# DPHY_RX0_VBUS2APB_WRAP_VBUSP_K3_DPHY_RX register map
Vendor: Texas Instruments
Peripheral module from a debugger description file (folder J7ES).
Registers are 32-bit, access per field, reset 0x0 unless marked. A register's access mark holds for its fields unless they carry their own. Offsets are as the file gives them; lines under a group give offsets from that group; [hi:lo] are bit positions; {n}, {i} and the like mark numbered series; 'fields as' and 'values as' point back to an identical list; <NAME> marks a mode.

## DPHY_RX0_VBUS2APB_WRAP_VBUSP_K3_DPHY_RX (part 1 of 2)
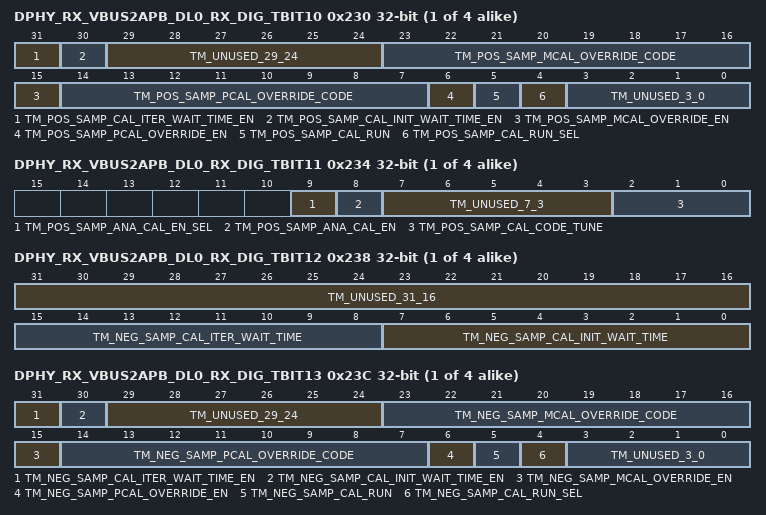
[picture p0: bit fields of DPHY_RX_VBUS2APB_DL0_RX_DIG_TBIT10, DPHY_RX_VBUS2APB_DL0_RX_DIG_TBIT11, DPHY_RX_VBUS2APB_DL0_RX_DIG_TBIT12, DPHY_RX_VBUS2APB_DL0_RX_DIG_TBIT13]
{0x230+0x100*i} DPHY_RX_VBUS2APB_DL{i}_RX_DIG_TBIT10 (i=0..3) — pos_samp_cal_ctrl_reg2
  [31] TM_POS_SAMP_CAL_ITER_WAIT_TIME_EN rw — posedge sampler calibration test mode iteration wait time enable
  [30] TM_POS_SAMP_CAL_INIT_WAIT_TIME_EN rw — posedge sampler calibration test mode initial wait time enable
  [29:24] TM_UNUSED_29_24 ro — RESERVED
  [23:16] TM_POS_SAMP_MCAL_OVERRIDE_CODE rw — posedge sampler calibration override mcal_code
  [15] TM_POS_SAMP_MCAL_OVERRIDE_EN rw — posedge sampler calibration mcal_code override en
  [14:7] TM_POS_SAMP_PCAL_OVERRIDE_CODE rw — posedge sampler calibration override pcal_code
  [6] TM_POS_SAMP_PCAL_OVERRIDE_EN rw — posedge sampler calibration pcal_code override en
  [5] TM_POS_SAMP_CAL_RUN rw — posedge sampler calibration test mode run
  [4] TM_POS_SAMP_CAL_RUN_SEL rw — posedge sampler calibration test mode selection
  [3:0] TM_UNUSED_3_0 ro — RESERVED
{0x234+0x100*i} DPHY_RX_VBUS2APB_DL{i}_RX_DIG_TBIT11 (i=0..3) — pos_samp_cal_ctrl_reg3
  [9] TM_POS_SAMP_ANA_CAL_EN_SEL rw — posedge sampler calibration analog calib enable selection
  [8] TM_POS_SAMP_ANA_CAL_EN rw — posedge sampler calibration analog calibration enable
  [7:3] TM_UNUSED_7_3 ro — RESERVED
  [2:0] TM_POS_SAMP_CAL_CODE_TUNE rw — posedge sampler calibration tune code
{0x238+0x100*i} DPHY_RX_VBUS2APB_DL{i}_RX_DIG_TBIT12 (i=0..3) — neg_samp_cal_ctrl_reg1
  [31:16] TM_UNUSED_31_16 ro — RESERVED
  [15:8] TM_NEG_SAMP_CAL_ITER_WAIT_TIME rw — negedge sampler calibration ieration time between codes
  [7:0] TM_NEG_SAMP_CAL_INIT_WAIT_TIME rw — negedge sampler calibration initial wait time
{0x23C+0x100*i} DPHY_RX_VBUS2APB_DL{i}_RX_DIG_TBIT13 (i=0..3) — neg_samp_cal_ctrl_reg2
  [31] TM_NEG_SAMP_CAL_ITER_WAIT_TIME_EN rw — negedge sampler calibration test mode iteration wait time enable
  [30] TM_NEG_SAMP_CAL_INIT_WAIT_TIME_EN rw — negedge sampler calibration test mode initial wait time enable
  [29:24] TM_UNUSED_29_24 ro — RESERVED
  [23:16] TM_NEG_SAMP_MCAL_OVERRIDE_CODE rw — negedge sampler calibration override mcal_code
  [15] TM_NEG_SAMP_MCAL_OVERRIDE_EN rw — negedge sampler calibration mcal_code override en
  [14:7] TM_NEG_SAMP_PCAL_OVERRIDE_CODE rw — negedge sampler calibration override pcal_code
  [6] TM_NEG_SAMP_PCAL_OVERRIDE_EN rw — negedge sampler calibration pcal_code override en
  [5] TM_NEG_SAMP_CAL_RUN rw — negedge sampler calibration test mode run
  [4] TM_NEG_SAMP_CAL_RUN_SEL rw — negedge sampler calibration test mode selection
  [3:0] TM_UNUSED_3_0 ro — RESERVED
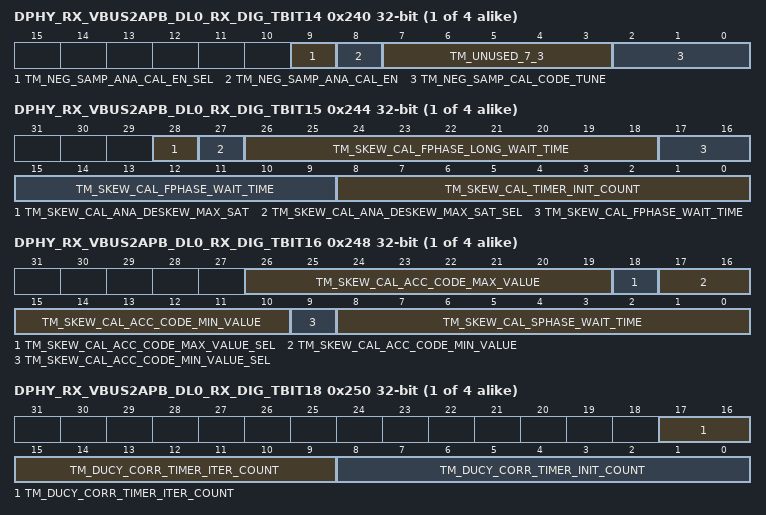
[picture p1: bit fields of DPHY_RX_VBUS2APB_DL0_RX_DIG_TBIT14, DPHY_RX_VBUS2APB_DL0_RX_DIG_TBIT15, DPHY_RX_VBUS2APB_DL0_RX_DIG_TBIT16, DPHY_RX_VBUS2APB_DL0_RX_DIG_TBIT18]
{0x240+0x100*i} DPHY_RX_VBUS2APB_DL{i}_RX_DIG_TBIT14 (i=0..3) — neg_samp_cal_ctrl_reg3
  [9] TM_NEG_SAMP_ANA_CAL_EN_SEL rw — negedge sampler calibration analog calib enable selection
  [8] TM_NEG_SAMP_ANA_CAL_EN rw — negedge sampler calibration analog calibration enable
  [7:3] TM_UNUSED_7_3 ro — RESERVED
  [2:0] TM_NEG_SAMP_CAL_CODE_TUNE rw — negedge sampler calibration tune code
{0x244+0x100*i} DPHY_RX_VBUS2APB_DL{i}_RX_DIG_TBIT15 (i=0..3) — skew_cal_fsm_reg1
  [28] TM_SKEW_CAL_ANA_DESKEW_MAX_SAT rw — skew calibration analog max satiration test mode enable
  [27] TM_SKEW_CAL_ANA_DESKEW_MAX_SAT_SEL rw — skew calibration analog max satiration selection
  [26:18] TM_SKEW_CAL_FPHASE_LONG_WAIT_TIME rw — skew calibration fast phase long wait time
  [17:9] TM_SKEW_CAL_FPHASE_WAIT_TIME rw — skew calibration fast phase wait time
  [8:0] TM_SKEW_CAL_TIMER_INIT_COUNT rw — skew calibration initial wait time
{0x248+0x100*i} DPHY_RX_VBUS2APB_DL{i}_RX_DIG_TBIT16 (i=0..3) — skew_cal_fsm_reg2
  [26:19] TM_SKEW_CAL_ACC_CODE_MAX_VALUE rw — skew calibration delay code test mode max value
  [18] TM_SKEW_CAL_ACC_CODE_MAX_VALUE_SEL rw — skew calibration max code test reg selection
  [17:10] TM_SKEW_CAL_ACC_CODE_MIN_VALUE rw — skew calibration delay code test mode min value
  [9] TM_SKEW_CAL_ACC_CODE_MIN_VALUE_SEL rw — skew calibration min code test reg selection
  [8:0] TM_SKEW_CAL_SPHASE_WAIT_TIME rw — skew calibration slow phase wait time
{0x24C+0x100*i} DPHY_RX_VBUS2APB_DL{i}_RX_DIG_TBIT17 (i=0..3) — skew_cal_fsm_reg3
  [7:0] TM_SKEW_CAL_DESKEW_START_CODE rw — skew calibration initial start code
{0x250+0x100*i} DPHY_RX_VBUS2APB_DL{i}_RX_DIG_TBIT18 (i=0..3) — ducy_corr_ctrl_reg1
  [17:9] TM_DUCY_CORR_TIMER_ITER_COUNT rw — duty cycle correction iteration wait time specified in this register will be considered when a non-zero value is speci fied here
  [8:0] TM_DUCY_CORR_TIMER_INIT_COUNT rw — duty cycle correction initial wait time specified in this register will be considered when a non-zero value is speci fied here
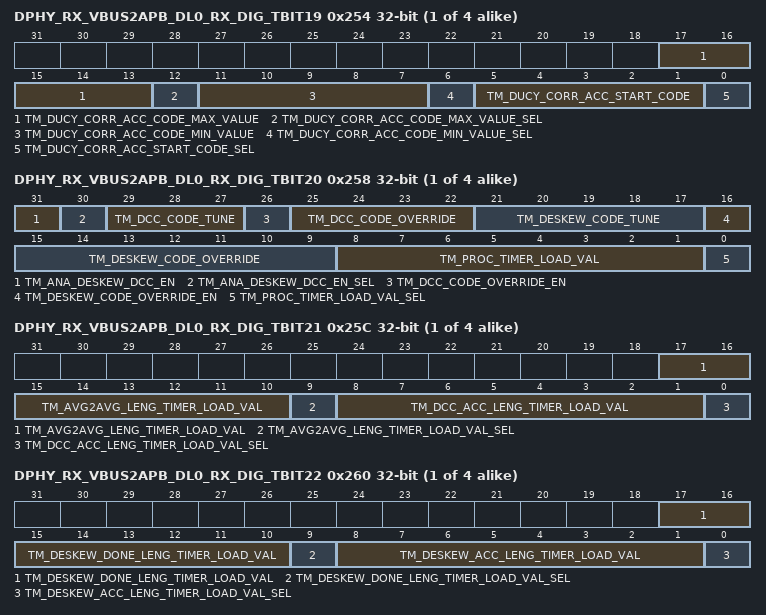
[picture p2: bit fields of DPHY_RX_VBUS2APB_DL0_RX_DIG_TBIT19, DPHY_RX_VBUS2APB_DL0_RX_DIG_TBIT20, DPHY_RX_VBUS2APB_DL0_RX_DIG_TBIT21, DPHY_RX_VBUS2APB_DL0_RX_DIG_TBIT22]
{0x254+0x100*i} DPHY_RX_VBUS2APB_DL{i}_RX_DIG_TBIT19 (i=0..3) — ducy_corr_ctrl_reg2
  [17:13] TM_DUCY_CORR_ACC_CODE_MAX_VALUE rw — duty cycle correction test mode max value
  [12] TM_DUCY_CORR_ACC_CODE_MAX_VALUE_SEL rw — duty cycle correction test mode max value selection
  [11:7] TM_DUCY_CORR_ACC_CODE_MIN_VALUE rw — duty cycle correction test mode min value
  [6] TM_DUCY_CORR_ACC_CODE_MIN_VALUE_SEL rw — duty cycle correction test mode min value selection
  [5:1] TM_DUCY_CORR_ACC_START_CODE rw — duty cycle correction test mode start code
  [0] TM_DUCY_CORR_ACC_START_CODE_SEL rw — duty cycle correction test mode start code selection
{0x258+0x100*i} DPHY_RX_VBUS2APB_DL{i}_RX_DIG_TBIT20 rw (i=0..3) — skew_cal_avg_reg1
  [31] TM_ANA_DESKEW_DCC_EN — test mode analog deskew enable
  [30] TM_ANA_DESKEW_DCC_EN_SEL — test mode deskew analog enable selection
  [29:27] TM_DCC_CODE_TUNE — duty cycle correction code tune
  [26] TM_DCC_CODE_OVERRIDE_EN — duty cycle correction code override enable
  [25:22] TM_DCC_CODE_OVERRIDE — duty cycle correction override code
  [21:17] TM_DESKEW_CODE_TUNE — skew calibration delay line code tune
  [16] TM_DESKEW_CODE_OVERRIDE_EN — skew calibration delay code override enable
  [15:9] TM_DESKEW_CODE_OVERRIDE — skew calibration delay line override code
  [8:1] TM_PROC_TIMER_LOAD_VAL — skew calibration process time test mode value
  [0] TM_PROC_TIMER_LOAD_VAL_SEL — skew calibration process time test mode value selection
{0x25C+0x100*i} DPHY_RX_VBUS2APB_DL{i}_RX_DIG_TBIT21 (i=0..3) — skew_cal_avg_reg2
  [17:10] TM_AVG2AVG_LENG_TIMER_LOAD_VAL rw — delay line code averaging to dcc code averaging wait time
  [9] TM_AVG2AVG_LENG_TIMER_LOAD_VAL_SEL rw — delay line code averaging to dcc code averaging wait time selection
  [8:1] TM_DCC_ACC_LENG_TIMER_LOAD_VAL rw — total number of dcc codes to be taken for averaging in test mode
  [0] TM_DCC_ACC_LENG_TIMER_LOAD_VAL_SEL rw — test mode selection value for test mode number of dcc codes under averaging
{0x260+0x100*i} DPHY_RX_VBUS2APB_DL{i}_RX_DIG_TBIT22 (i=0..3) — skew_cal_avg_reg3
  [17:10] TM_DESKEW_DONE_LENG_TIMER_LOAD_VAL rw — after skew calibration is done, length of wait timer
  [9] TM_DESKEW_DONE_LENG_TIMER_LOAD_VAL_SEL rw — test mode selection value for length of wait time after deskew
  [8:1] TM_DESKEW_ACC_LENG_TIMER_LOAD_VAL rw — number of deskew dealy codes to be taken for averaging
  [0] TM_DESKEW_ACC_LENG_TIMER_LOAD_VAL_SEL rw — tets mode selction for test mode number of delay line codes for averaging
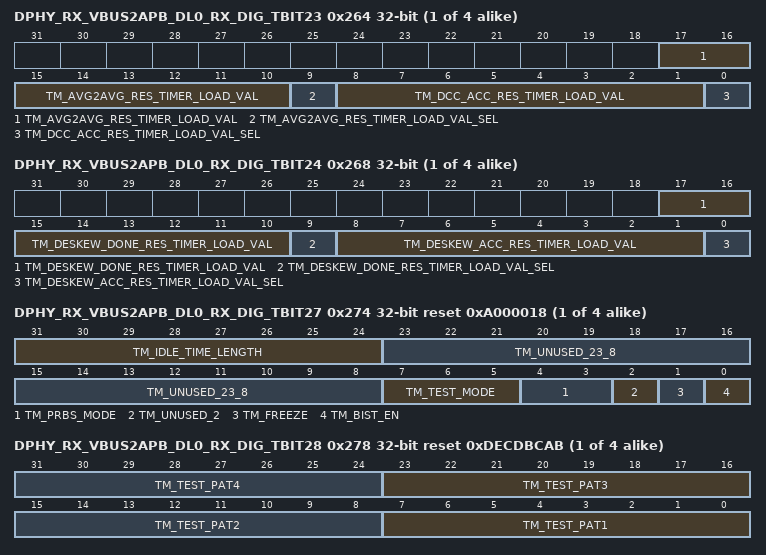
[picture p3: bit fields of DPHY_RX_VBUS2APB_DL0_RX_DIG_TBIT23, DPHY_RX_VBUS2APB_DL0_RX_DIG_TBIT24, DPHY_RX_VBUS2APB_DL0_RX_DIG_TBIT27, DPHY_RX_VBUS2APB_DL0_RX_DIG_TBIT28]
{0x264+0x100*i} DPHY_RX_VBUS2APB_DL{i}_RX_DIG_TBIT23 (i=0..3) — skew_cal_avg_reg4
  [17:10] TM_AVG2AVG_RES_TIMER_LOAD_VAL rw — resolution time of dcc averaging to deskew averaging wait time in test mode
  [9] TM_AVG2AVG_RES_TIMER_LOAD_VAL_SEL rw — test mode selection of resolution time of dcc averaging to deskew averaging wait time
  [8:1] TM_DCC_ACC_RES_TIMER_LOAD_VAL rw — resolution time of dcc averaging wait time in test mode
  [0] TM_DCC_ACC_RES_TIMER_LOAD_VAL_SEL rw — test mode selection of resolution time of dcc averaging wait time
{0x268+0x100*i} DPHY_RX_VBUS2APB_DL{i}_RX_DIG_TBIT24 (i=0..3) — skew_cal_avg_reg5
  [17:10] TM_DESKEW_DONE_RES_TIMER_LOAD_VAL rw — resolution time of deskew done wait time in test mode
  [9] TM_DESKEW_DONE_RES_TIMER_LOAD_VAL_SEL rw — test mode selcetion of resolution time of deskew done wait time in test mode
  [8:1] TM_DESKEW_ACC_RES_TIMER_LOAD_VAL rw — resolution time of deskew averaging wait time in test mode
  [0] TM_DESKEW_ACC_RES_TIMER_LOAD_VAL_SEL rw — tets mode selection of resolution time of deskew averaging wait time in test mode
{0x26C+0x100*i} DPHY_RX_VBUS2APB_DL{i}_RX_DIG_TBIT25 ro (i=0..3) — DIGITAL_EXTRA_CALIB_REG0
  [31:0] DIG_CALIB_EXTRA_TBIT0 — RESERVED
{0x270+0x100*i} DPHY_RX_VBUS2APB_DL{i}_RX_DIG_TBIT26 ro (i=0..3) — DIGITAL_EXTRA_CALIB_REG1
  [31:0] DIG_CALIB_EXTRA_TBIT1 — RESERVED
{0x274+0x100*i} DPHY_RX_VBUS2APB_DL{i}_RX_DIG_TBIT27 reset 0xA000018 (i=0..3) — bist_config_reg1
  [31:24] TM_IDLE_TIME_LENGTH rw — BIST_IDLE_TIME
  [23:8] TM_UNUSED_23_8 ro — RESERVED
  [7:5] TM_TEST_MODE rw — PRBS mode - when set to '1' PRBS mode is selected
  [4:3] TM_PRBS_MODE rw — BIST PRBS MODE 9 when 0x0
  [2] TM_UNUSED_2 ro — RESERVED
  [1] TM_FREEZE rw — Freeze the LFSR contents after every packet or frame
  [0] TM_BIST_EN rw — Enable signal for pattern checker
{0x278+0x100*i} DPHY_RX_VBUS2APB_DL{i}_RX_DIG_TBIT28 rw reset 0xDECDBCAB (i=0..3) — bist_config_reg2
  [8n-1:8n-8] TM_TEST_PAT{n} (n=1..4) — User registers to specify the BIST data{n} Based on the deault_mode setting design will consider either of the hard-value from RTL [or] the soft-value provided here
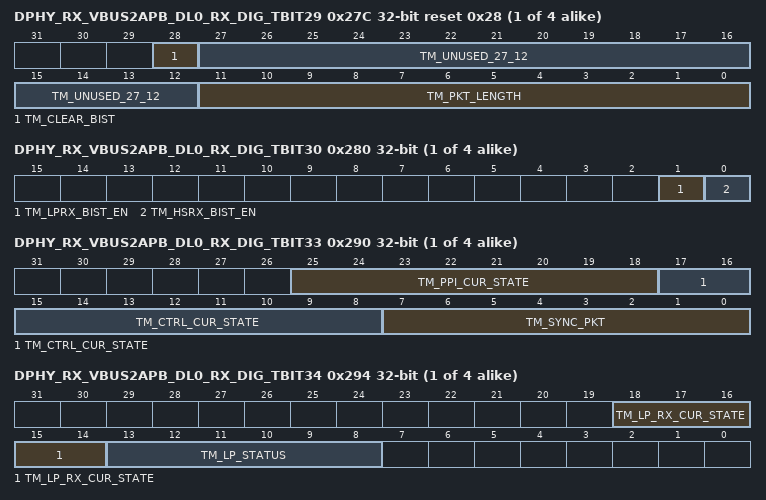
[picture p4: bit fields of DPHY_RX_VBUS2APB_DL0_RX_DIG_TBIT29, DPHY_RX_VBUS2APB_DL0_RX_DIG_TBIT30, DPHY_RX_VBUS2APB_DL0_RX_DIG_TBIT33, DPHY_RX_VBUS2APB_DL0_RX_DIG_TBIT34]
{0x27C+0x100*i} DPHY_RX_VBUS2APB_DL{i}_RX_DIG_TBIT29 reset 0x28 (i=0..3) — bist_config_reg3
  [28] TM_CLEAR_BIST rw — Setting this will clear all the BIST related flags and counters
  [27:12] TM_UNUSED_27_12 ro — RESERVED
  [11:0] TM_PKT_LENGTH rw — Based on the default_mode design will consider the run-length from design or the programmed value specified here
{0x280+0x100*i} DPHY_RX_VBUS2APB_DL{i}_RX_DIG_TBIT30 (i=0..3) — bist_config_reg4
  [1] TM_LPRX_BIST_EN rw — LPRX BIST is enbaled - rxda_lprx_bist_en - When '1', LP BIST is enabled
  [0] TM_HSRX_BIST_EN rw — HSRX BIST is enbaled - rxda_hsrx_bist_en - when '1', HS BIST is enabled
{0x284+0x100*i} DPHY_RX_VBUS2APB_DL{i}_RX_DIG_TBIT31 ro (i=0..3) — DIGITAL_EXTRA_TEST_REG1
  [31:0] DIG_EXTRA_FUNC_TBIT1 — RESERVED
{0x288+0x100*i} DPHY_RX_VBUS2APB_DL{i}_RX_DIG_TBIT32 ro (i=0..3) — DIGITAL_EXTRA_TEST_REG2
  [31:0] DIG_EXTRA_FUNC_TBIT2 — RESERVED
{0x28C+0x100*i} DPHY_RX_VBUS2APB_DL{i}_RX_ANA_TBIT2 ro (i=0..3) — ANA_TBIT0
  [31:0] ANA_READ_TBIT0 — Analog read register 0
{0x290+0x100*i} DPHY_RX_VBUS2APB_DL{i}_RX_DIG_TBIT33 ro (i=0..3) — deserialiser_fsm_status
  [25:18] TM_PPI_CUR_STATE — Current State of the SYNC detection FSM during the HS data receive mode or skew calibration mode
  [17:8] TM_CTRL_CUR_STATE — current state status of HS receive FSM
  [7:0] TM_SYNC_PKT — Status of received SYNC packet
{0x294+0x100*i} DPHY_RX_VBUS2APB_DL{i}_RX_DIG_TBIT34 ro (i=0..3) — lp_status
  [18:14] TM_LP_RX_CUR_STATE — Current state of LP receiver FSM
  [13:8] TM_LP_STATUS — Status of DP,DN pins of LPRX, LPCD, ULPRX respectively
{0x298+0x100*i} DPHY_RX_VBUS2APB_DL{i}_RX_DIG_TBIT35 ro (i=0..3) — DIGITAL_EXTRA_READ_REG0
  [31:0] DIG_EXTRA_READ_TBIT0 — RESERVED
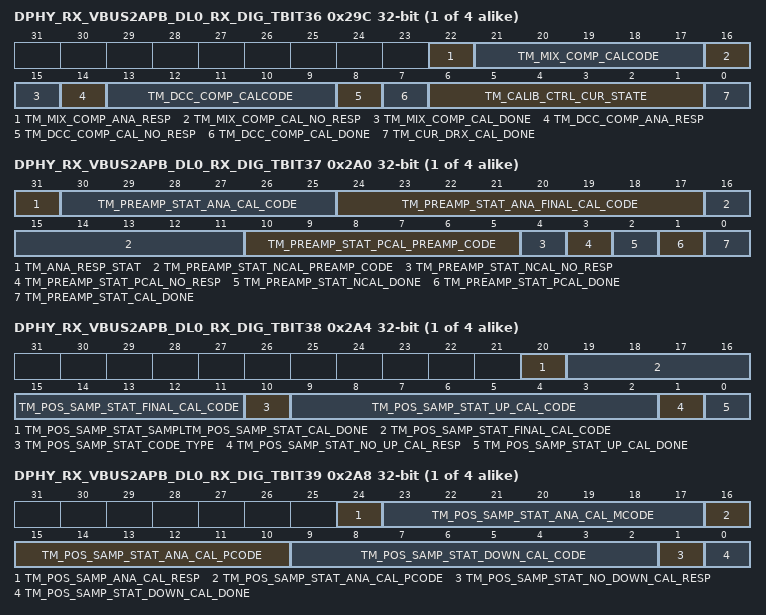
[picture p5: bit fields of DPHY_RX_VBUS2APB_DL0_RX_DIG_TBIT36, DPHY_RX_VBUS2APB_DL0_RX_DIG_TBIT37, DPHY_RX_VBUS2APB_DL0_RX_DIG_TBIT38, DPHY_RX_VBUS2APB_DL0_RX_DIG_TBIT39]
{0x29C+0x100*i} DPHY_RX_VBUS2APB_DL{i}_RX_DIG_TBIT36 ro (i=0..3) — dcc_mixer_comparator_calibration_stat
  [22] TM_MIX_COMP_ANA_RESP — Mixer comparator analog response
  [21:17] TM_MIX_COMP_CALCODE — Mixer comparator calibration code
  [16] TM_MIX_COMP_CAL_NO_RESP — Mixer comparator calibration has no response from analog
  [15] TM_MIX_COMP_CAL_DONE — Mixer comparator calibration is done properly
  [14] TM_DCC_COMP_ANA_RESP — Duty Cycle Comparator analog response
  [13:9] TM_DCC_COMP_CALCODE — Duty cycle corrector comparator calibration code
  [8] TM_DCC_COMP_CAL_NO_RESP — Duty cycle corrector comparator calibration has no response from analog
  [7] TM_DCC_COMP_CAL_DONE — Duty cycle corrector comparator calibration is done properly
  [6:1] TM_CALIB_CTRL_CUR_STATE — If struck, indicates calibration FSM current state
  [0] TM_CUR_DRX_CAL_DONE — Current DRX DPHY_RX_VBUS2APB_LANE calibrations are done
{0x2A0+0x100*i} DPHY_RX_VBUS2APB_DL{i}_RX_DIG_TBIT37 ro (i=0..3) — preamp_cal_status_reg1
  [31] TM_ANA_RESP_STAT — current analog or test mode response for which calibration is happening
  [30:25] TM_PREAMP_STAT_ANA_CAL_CODE — code going to analog
  [24:17] TM_PREAMP_STAT_ANA_FINAL_CAL_CODE — code decided to send to analog before tune
  [16:11] TM_PREAMP_STAT_NCAL_PREAMP_CODE — calib code in posedge_data run
  [10:5] TM_PREAMP_STAT_PCAL_PREAMP_CODE — calib code in negedge_data run
  [4] TM_PREAMP_STAT_NCAL_NO_RESP — negedge_data run ha sno response
  [3] TM_PREAMP_STAT_PCAL_NO_RESP — posedge_data run ha sno response
  [2] TM_PREAMP_STAT_NCAL_DONE — negedge_data cal run is done
  [1] TM_PREAMP_STAT_PCAL_DONE — posedge_data cal run is done
  [0] TM_PREAMP_STAT_CAL_DONE — preamp calibration is done
{0x2A4+0x100*i} DPHY_RX_VBUS2APB_DL{i}_RX_DIG_TBIT38 ro (i=0..3) — pos_samp_cal_status_reg1
  [20] TM_POS_SAMP_STAT_SAMPLTM_POS_SAMP_STAT_CAL_DONE — posedge sampler calibration is done
  [19:11] TM_POS_SAMP_STAT_FINAL_CAL_CODE — posedge sampler calbration final code
  [10] TM_POS_SAMP_STAT_CODE_TYPE — code type that is changing for posedge sampler
  [9:2] TM_POS_SAMP_STAT_UP_CAL_CODE — up check calib run code for posedge sampler
  [1] TM_POS_SAMP_STAT_NO_UP_CAL_RESP — up check calib run code has no analog response
  [0] TM_POS_SAMP_STAT_UP_CAL_DONE — up check calibration is done
{0x2A8+0x100*i} DPHY_RX_VBUS2APB_DL{i}_RX_DIG_TBIT39 ro (i=0..3) — pos_samp_cal_status_reg2
  [24] TM_POS_SAMP_ANA_CAL_RESP — test mode status of posedge sampler
  [23:17] TM_POS_SAMP_STAT_ANA_CAL_MCODE — final m code going to posedge sampler
  [16:10] TM_POS_SAMP_STAT_ANA_CAL_PCODE — final p code going to posedge sampler
  [9:2] TM_POS_SAMP_STAT_DOWN_CAL_CODE — down check calib run code for posedge sampler
  [1] TM_POS_SAMP_STAT_NO_DOWN_CAL_RESP — down check calib run code has no analog response
  [0] TM_POS_SAMP_STAT_DOWN_CAL_DONE — down check calibration is done
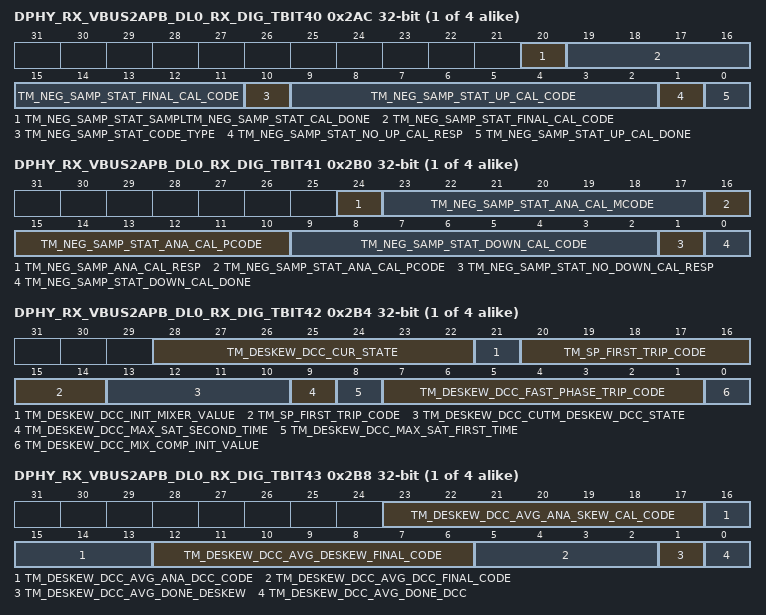
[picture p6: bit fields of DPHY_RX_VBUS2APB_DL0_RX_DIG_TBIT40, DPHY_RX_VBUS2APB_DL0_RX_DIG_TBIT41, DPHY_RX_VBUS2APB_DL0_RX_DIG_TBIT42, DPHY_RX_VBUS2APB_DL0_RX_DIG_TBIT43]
{0x2AC+0x100*i} DPHY_RX_VBUS2APB_DL{i}_RX_DIG_TBIT40 ro (i=0..3) — neg_samp_cal_status_reg1
  [20] TM_NEG_SAMP_STAT_SAMPLTM_NEG_SAMP_STAT_CAL_DONE — negedge sampler calibration is done
  [19:11] TM_NEG_SAMP_STAT_FINAL_CAL_CODE — negedge sampler calbration final code
  [10] TM_NEG_SAMP_STAT_CODE_TYPE — code type that is changing for negedge sampler
  [9:2] TM_NEG_SAMP_STAT_UP_CAL_CODE — up check calib run code for negedge sampler
  [1] TM_NEG_SAMP_STAT_NO_UP_CAL_RESP — up check calib run code has no analog response
  [0] TM_NEG_SAMP_STAT_UP_CAL_DONE — up check calibration is done
{0x2B0+0x100*i} DPHY_RX_VBUS2APB_DL{i}_RX_DIG_TBIT41 ro (i=0..3) — neg_samp_cal_status_reg2
  [24] TM_NEG_SAMP_ANA_CAL_RESP — test mode status of negedge sampler
  [23:17] TM_NEG_SAMP_STAT_ANA_CAL_MCODE — final m code going to negedge sampler
  [16:10] TM_NEG_SAMP_STAT_ANA_CAL_PCODE — final p code going to negedge sampler
  [9:2] TM_NEG_SAMP_STAT_DOWN_CAL_CODE — down check calib run code for negedge sampler
  [1] TM_NEG_SAMP_STAT_NO_DOWN_CAL_RESP — down check calib run code has no analog response
  [0] TM_NEG_SAMP_STAT_DOWN_CAL_DONE — down check calibration is done
{0x2B4+0x100*i} DPHY_RX_VBUS2APB_DL{i}_RX_DIG_TBIT42 ro (i=0..3) — skew_cal_fsm_status_reg1
  [28:22] TM_DESKEW_DCC_CUR_STATE — Duty cycle correction logic current state
  [21] TM_DESKEW_DCC_INIT_MIXER_VALUE — Duty cycle correction initial comparator value
  [20:14] TM_SP_FIRST_TRIP_CODE — slow phase first trip code
  [13:10] TM_DESKEW_DCC_CUTM_DESKEW_DCC_STATE — current state of the deskew FSM
  [9] TM_DESKEW_DCC_MAX_SAT_SECOND_TIME — if asserted, deskew FSM has gone into max saturation second time
  [8] TM_DESKEW_DCC_MAX_SAT_FIRST_TIME — if asserted, deskew FSM has got saturated once
  [7:1] TM_DESKEW_DCC_FAST_PHASE_TRIP_CODE — deskew FSM fast phase trip code
  [0] TM_DESKEW_DCC_MIX_COMP_INIT_VALUE — deskew algorithm mixer initial value
{0x2B8+0x100*i} DPHY_RX_VBUS2APB_DL{i}_RX_DIG_TBIT43 ro (i=0..3) — skew_cal_avg_status_reg1
  [23:17] TM_DESKEW_DCC_AVG_ANA_SKEW_CAL_CODE — final code going to delay line
  [16:13] TM_DESKEW_DCC_AVG_ANA_DCC_CODE — final code going to duty cycle corrector
  [12:6] TM_DESKEW_DCC_AVG_DESKEW_FINAL_CODE — delay line code before tuning
  [5:2] TM_DESKEW_DCC_AVG_DCC_FINAL_CODE — ducy code before tuning
  [1] TM_DESKEW_DCC_AVG_DONE_DESKEW — skew calibration is done
  [0] TM_DESKEW_DCC_AVG_DONE_DCC — duty cycle correction is done
{0x2BC+0x100*i} DPHY_RX_VBUS2APB_DL{i}_RX_DIG_TBIT44 ro (i=0..3) — skew_cal_avg_status_reg2
  [16:0] TM_DESKEW_DCC_AVG_CUTM_DESKEW_DCC_AVG_STATE — current state of deskew_dcc_averaging FSM
{0x2C0+0x100*i} DPHY_RX_VBUS2APB_DL{i}_RX_DIG_TBIT45 ro (i=0..3) — DIGITAL_CALIB_EXTRA_READ_REG0
  [31:0] DIG_CALIBRATION_EXTRA_READ_TBIT0 — RESERVED
{0x2C4+0x100*i} DPHY_RX_VBUS2APB_DL{i}_RX_DIG_TBIT46 ro (i=0..3) — DIGITAL_CALIB_EXTRA_READ_REG1
  [31:0] DIG_CALIBRATION_EXTRA_READ_TBIT1 — RESERVED
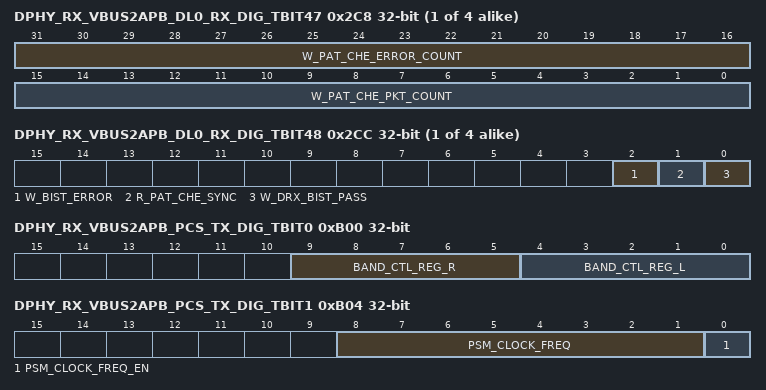
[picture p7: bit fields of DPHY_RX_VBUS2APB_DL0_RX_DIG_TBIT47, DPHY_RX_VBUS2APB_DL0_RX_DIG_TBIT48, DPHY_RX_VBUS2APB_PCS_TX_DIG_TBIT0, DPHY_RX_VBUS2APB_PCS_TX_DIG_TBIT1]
{0x2C8+0x100*i} DPHY_RX_VBUS2APB_DL{i}_RX_DIG_TBIT47 ro (i=0..3) — bist_status_reg1
  [31:16] W_PAT_CHE_ERROR_COUNT — BIST Pattern checker error count's live status can be obtained by poling this field
  [15:0] W_PAT_CHE_PKT_COUNT — BIST packet count's live status can be obtained by poling this field
{0x2CC+0x100*i} DPHY_RX_VBUS2APB_DL{i}_RX_DIG_TBIT48 ro (i=0..3) — bist_status_reg2
  [2] W_BIST_ERROR — Status of HS data path comparision outcome, '0' means pass
  [1] R_PAT_CHE_SYNC — Informs BIST Pattern checker is not in sync with pattern generator - Check polarity
  [0] W_DRX_BIST_PASS — Entire DRX has passed BIST when this bit's status is set
{0x2D0+0x100*i} DPHY_RX_VBUS2APB_DL{i}_RX_DIG_TBIT49 ro (i=0..3) — DIG_BIST_EXTRA_READ_REG0
  [31:0] DIG_BIST_EXTRA_READ_TBIT0 — RESERVED
{0x2D4+0x100*i} DPHY_RX_VBUS2APB_DL{i}_RX_DIG_TBIT50 ro (i=0..3) — DIG_EXTRA_READ_REG1
  [31:0] DIG_EXTRA_READ_TBIT1 — RESERVED
{0x2D8+0x100*i} DPHY_RX_VBUS2APB_DL{i}_RX_DIG_TBIT51 ro (i=0..3) — DIG_EXTRA_READ_REG2
  [31:0] DIG_EXTRA_READ_TBIT2 — RESERVED
0xB00 DPHY_RX_VBUS2APB_PCS_TX_DIG_TBIT0 — PHY_BAND_CONTROL
  [9:5] BAND_CTL_REG_R rw — Data Rate [80_100] MHz
  [4:0] BAND_CTL_REG_L rw — Data Rate [80_100] MHz
0xB04 DPHY_RX_VBUS2APB_PCS_TX_DIG_TBIT1 — PHY_PSM_CONFIG
  [8:1] PSM_CLOCK_FREQ rw — psm_clock freq value
  [0] PSM_CLOCK_FREQ_EN rw — take psm_clock_freq from tbit
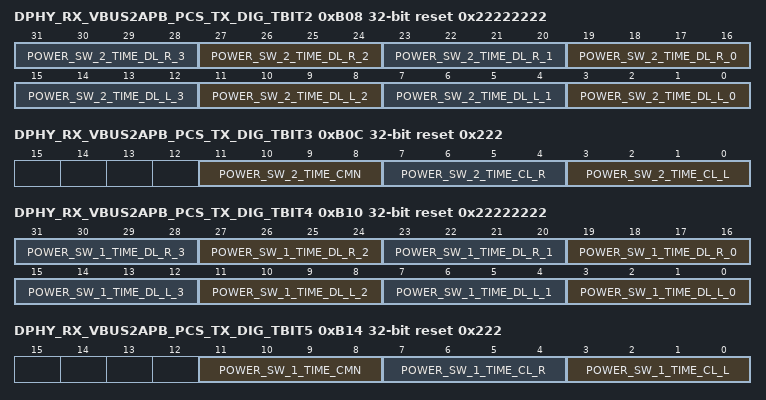
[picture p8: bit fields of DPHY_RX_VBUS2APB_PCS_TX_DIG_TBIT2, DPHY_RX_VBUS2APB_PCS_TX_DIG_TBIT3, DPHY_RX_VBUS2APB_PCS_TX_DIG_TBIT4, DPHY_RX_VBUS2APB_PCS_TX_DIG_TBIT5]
0xB08 DPHY_RX_VBUS2APB_PCS_TX_DIG_TBIT2 rw reset 0x22222222 — PHY_PI_PH2_DL_CONFIG
  [4n+19:4n+16] POWER_SW_2_TIME_DL_R_{n} (n=0..3), [4n+3:4n] POWER_SW_2_TIME_DL_L_{n} (n=0..3)
0xB0C DPHY_RX_VBUS2APB_PCS_TX_DIG_TBIT3 reset 0x222 — PHY_PI_PH2_CL_CMN_CONFIG
  [11:8] POWER_SW_2_TIME_CMN rw, [7:4] POWER_SW_2_TIME_CL_R rw, [3:0] POWER_SW_2_TIME_CL_L rw
0xB10 DPHY_RX_VBUS2APB_PCS_TX_DIG_TBIT4 rw reset 0x22222222 — PHY_PI_PH1_DL_CONFIG
  [4n+19:4n+16] POWER_SW_1_TIME_DL_R_{n} (n=0..3), [4n+3:4n] POWER_SW_1_TIME_DL_L_{n} (n=0..3)
0xB14 DPHY_RX_VBUS2APB_PCS_TX_DIG_TBIT5 reset 0x222 — PHY_PI_PH1_CL_CMN_CONFIG
  [11:8] POWER_SW_1_TIME_CMN rw, [7:4] POWER_SW_1_TIME_CL_R rw, [3:0] POWER_SW_1_TIME_CL_L rw
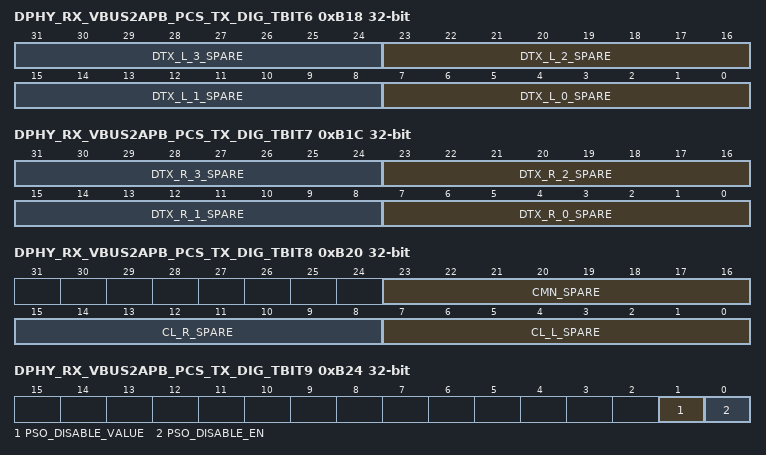
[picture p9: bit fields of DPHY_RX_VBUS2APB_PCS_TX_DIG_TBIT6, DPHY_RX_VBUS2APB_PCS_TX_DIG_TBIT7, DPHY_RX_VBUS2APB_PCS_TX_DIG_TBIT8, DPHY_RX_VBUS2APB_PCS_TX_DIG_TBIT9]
0xB18 DPHY_RX_VBUS2APB_PCS_TX_DIG_TBIT6 rw — PHY_DL_SPARE_LEFT
  [8n+7:8n] DTX_L_{n}_SPARE (n=0..3) — dtx_l_{n} spare port
0xB1C DPHY_RX_VBUS2APB_PCS_TX_DIG_TBIT7 rw — PHY_DL_SPARE_RIGHT
  [8n+7:8n] DTX_R_{n}_SPARE (n=0..3) — dtx_r_{n} spare port
0xB20 DPHY_RX_VBUS2APB_PCS_TX_DIG_TBIT8 — PHY_CL_CMN_SPARE
  [23:16] CMN_SPARE rw — cmn spare port
  [15:8] CL_R_SPARE rw — cl_r spare port
  [7:0] CL_L_SPARE rw — cl_l spare port
0xB24 DPHY_RX_VBUS2APB_PCS_TX_DIG_TBIT9 — PHY_PI_CONFIG
  [1] PSO_DISABLE_VALUE rw — pso_disbale value
  [0] PSO_DISABLE_EN rw — take pso_diable from tbit
0xB28 DPHY_RX_VBUS2APB_PCS_TX_DIG_TBIT10 rw — DIG_TBIT10
  [31:0] DIG_TBIT10 — Digital Test Register Extra 4
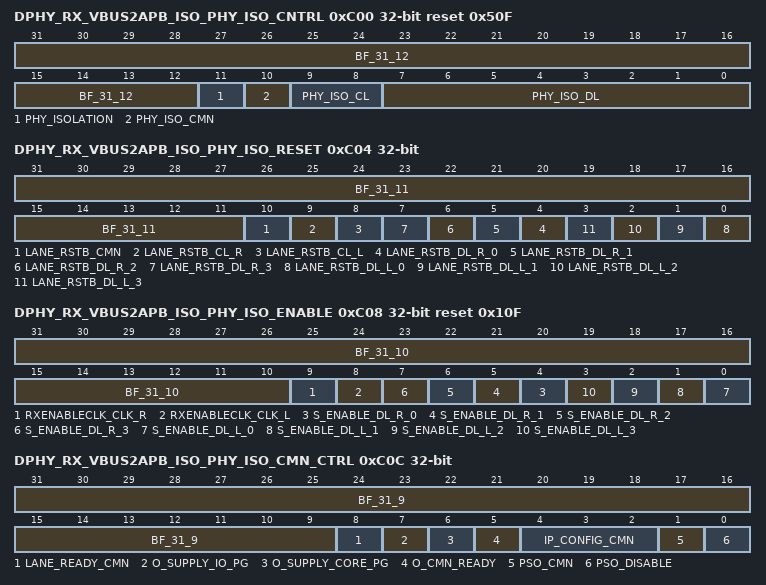
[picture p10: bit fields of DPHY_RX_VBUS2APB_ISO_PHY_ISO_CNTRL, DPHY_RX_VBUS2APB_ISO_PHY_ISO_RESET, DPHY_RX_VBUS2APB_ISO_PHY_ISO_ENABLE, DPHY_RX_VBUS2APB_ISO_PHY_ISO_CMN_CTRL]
0xC00 DPHY_RX_VBUS2APB_ISO_PHY_ISO_CNTRL reset 0x50F — PHY_ISO_CNTRL
  [31:12] BF_31_12 ro
  [11] PHY_ISOLATION rw — when set enables phy_isolation
  [10] PHY_ISO_CMN rw — This bit enables the Isolation on Common Lane
  [9:8] PHY_ISO_CL rw — Bit
  [7:0] PHY_ISO_DL rw — Bit
0xC04 DPHY_RX_VBUS2APB_ISO_PHY_ISO_RESET — PHY_ISO_RESET
  [31:11] BF_31_11 ro
  [10] LANE_RSTB_CMN rw — Drives the Lane Reset for Common lane_rstb_cmn
  [9] LANE_RSTB_CL_R rw — Drives the Right Clock Lane Reset lane_rstb_cl_l
  [8] LANE_RSTB_CL_L rw — Drives the Left Clock Lane Reset lane_rstb_cl_l
  [n+4] LANE_RSTB_DL_R_{n} rw (n=0..3) — Drives the Data Lane {n} Right Link Reset lane_rstb_dl_{n+4}
  [n] LANE_RSTB_DL_L_{n} rw (n=0..3) — Drives the Data Lane {n} Left Link Reset lane_rstb_dl_{n}
0xC08 DPHY_RX_VBUS2APB_ISO_PHY_ISO_ENABLE reset 0x10F — PHY_ISO_ENABLE
  [31:10] BF_31_10 ro
  [9] RXENABLECLK_CLK_R rw — Drives to enable the right clock DPHY_RX_VBUS2APB_LANE TxEnableClk_clk_r
  [8] RXENABLECLK_CLK_L rw — Drives to enable the left clock DPHY_RX_VBUS2APB_LANE TxEnableClk_clk_l
  [n+4] S_ENABLE_DL_R_{n} rw (n=0..3) — Enables the Data Lane {n} Right Link M_Enable_dl_{n+4}
  [n] S_ENABLE_DL_L_{n} rw (n=0..3) — Enables the Data Lane {n} Left Link M_Enable_dl_{n}
0xC0C DPHY_RX_VBUS2APB_ISO_PHY_ISO_CMN_CTRL — PHY_ISO_CMN_CTRL
  [31:9] BF_31_9 ro
  [8] LANE_READY_CMN ro — Drives lane_ready_cmn
  [7] O_SUPPLY_IO_PG ro — I/O supply power is good o_supply_io_pg
  [6] O_SUPPLY_CORE_PG ro — Core Supply Power is good o_supply_core_pg
  [5] O_CMN_READY ro — Common ready Indicator o_cmn_ready
  [4:2] IP_CONFIG_CMN rw — Drives the IP configuration to decide which clock DPHY_RX_VBUS2APB_LANE acts as the master DPHY_RX_VBUS2APB_LANE to all clock lanes ip_config_cmn
  [1] PSO_CMN rw — Drives the power shut off for the Common pso_cmn
  [0] PSO_DISABLE rw — Disable power shut off pso_disable
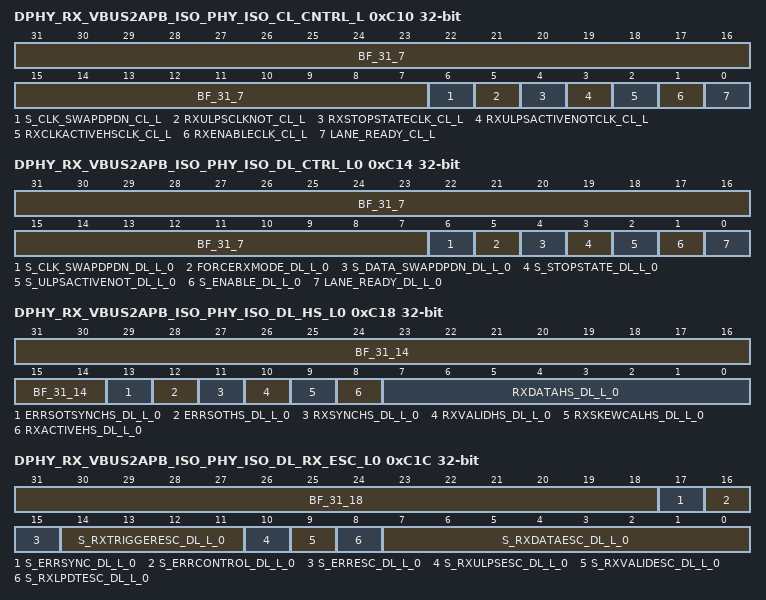
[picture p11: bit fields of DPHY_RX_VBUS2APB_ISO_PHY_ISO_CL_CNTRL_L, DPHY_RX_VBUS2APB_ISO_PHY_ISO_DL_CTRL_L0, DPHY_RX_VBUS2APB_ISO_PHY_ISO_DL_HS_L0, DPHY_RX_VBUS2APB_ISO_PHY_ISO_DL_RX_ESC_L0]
0xC10 DPHY_RX_VBUS2APB_ISO_PHY_ISO_CL_CNTRL_L — PHY_ISO_CL_CNTRL_L
  [31:7] BF_31_7 ro
  [6] S_CLK_SWAPDPDN_CL_L rw — Drives the value to enable the Swap of DP and DN signals inside the clock DPHY_RX_VBUS2APB_LANE S_Clk_SwapDpDn_cl_l
  [5] RXULPSCLKNOT_CL_L ro — Receives ULPS power state status RxULPSClkNot_cl_l
  [4] RXSTOPSTATECLK_CL_L ro — Receives DPHY_RX_VBUS2APB_LANE state status RxStopStateClk_cl_l
  [3] RXULPSACTIVENOTCLK_CL_L ro — Receives DPHY_RX_VBUS2APB_LANE ULPS active state status RxULPSActiveNotClk_cl_l
  [2] RXCLKACTIVEHSCLK_CL_L ro — Stores Receiver high speed active RxClkActiveHSClk_cl_l
  [1] RXENABLECLK_CL_L rw — Enable the Clock Lane RxEnableClk_cl_l
  [0] LANE_READY_CL_L ro — High speed clock transmission ready lane_ready_cl_l
0xC14 DPHY_RX_VBUS2APB_ISO_PHY_ISO_DL_CTRL_L0 — PHY_ISO_DL_CTRL_L0
  [31:7] BF_31_7 ro
  [6] S_CLK_SWAPDPDN_DL_L_0 rw — Drives S_Clk_SwapDpDn_dl_l_0
  [5] FORCERXMODE_DL_L_0 rw — Forces the DPHY_RX_VBUS2APB_LANE in Receiver mode ForceRxMode_dl_l_0
  [4] S_DATA_SWAPDPDN_DL_L_0 rw — Swaps the tx_p and tx_m differential pins S_Data_SwapDpDn_dl_l_0
  [3] S_STOPSTATE_DL_L_0 ro — Receives Lane Stop state status S_StopState_dl_l_0
  [2] S_ULPSACTIVENOT_DL_L_0 ro — Receives the Turnaround request S_ULPSActiveNot_dl_l_0
  [1] S_ENABLE_DL_L_0 rw — Enables the data DPHY_RX_VBUS2APB_LANE S_Enable_dl_l_0
  [0] LANE_READY_DL_L_0 ro — High Speed data DPHY_RX_VBUS2APB_LANE ready lane_ready_dl_l_0
0xC18 DPHY_RX_VBUS2APB_ISO_PHY_ISO_DL_HS_L0 ro — PHY_ISO_DL_HS_L0
  [31:14] BF_31_14
  [13] ERRSOTSYNCHS_DL_L_0 — Start of transmission error ErrSoTSyncHS_dl_l_0
  [12] ERRSOTHS_DL_L_0 — Start of transmission error ErrSoTHS_dl_l_0
  [11] RXSYNCHS_DL_L_0 — Stores the high speed receive synchronization RxSyncHS_dl_l_0
  [10] RXVALIDHS_DL_L_0 — High speed data receive data valid RxValidHS_dl_l_0
  [9] RXSKEWCALHS_DL_L_0 — High speed data receive dksew calibration RxSkewCalHS_dl_l_0
  [8] RXACTIVEHS_DL_L_0 — Stores the high speed data reception active RxActiveHS_dl_l_0
  [7:0] RXDATAHS_DL_L_0 — High speed receive data RxDataHS_dl_l_0
0xC1C DPHY_RX_VBUS2APB_ISO_PHY_ISO_DL_RX_ESC_L0 ro — PHY_ISO_DL_RX_ESC_L0
  [31:18] BF_31_18
  [17] S_ERRSYNC_DL_L_0 — Control error S_ErrControl_dl_l_0
  [16] S_ERRCONTROL_DL_L_0 — Control error S_ErrControl_dl_l_0
  [15] S_ERRESC_DL_L_0 — Escape entry error S_ErrEsc_dl_l_0
  [14:11] S_RXTRIGGERESC_DL_L_0 — Receive escape mode lower power trigger state S_RxTriggerEsc_dl_l_0
  [10] S_RXULPSESC_DL_L_0 — Receive escape mode ultra low power state S_RxULPSEsc_dl_l_0
  [9] S_RXVALIDESC_DL_L_0 — Receive escape mode data present S_RxValidEsc_dl_l_0
  [8] S_RXLPDTESC_DL_L_0 — Receive escape mode low power data indicator S_RxLPDTEsc_dl_l_0
  [7:0] S_RXDATAESC_DL_L_0 — Receive escape mode low power receive data S_RxDataEsc_dl_l_0
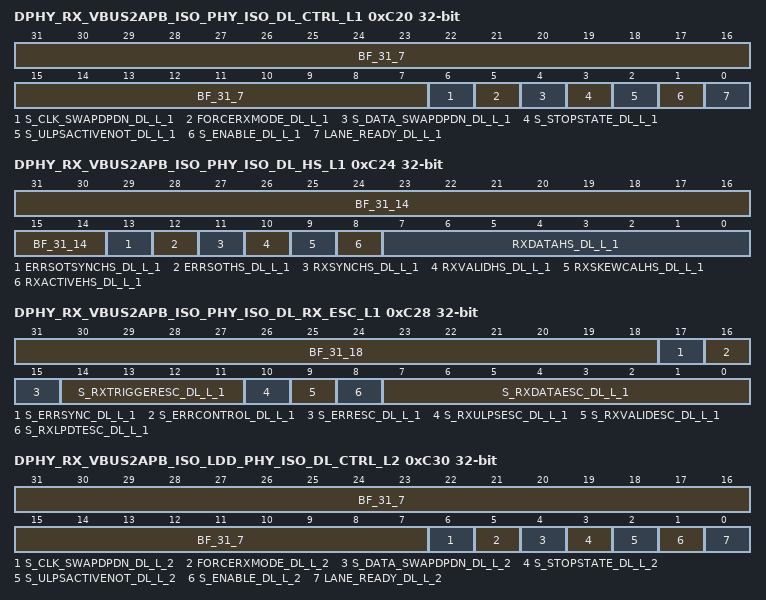
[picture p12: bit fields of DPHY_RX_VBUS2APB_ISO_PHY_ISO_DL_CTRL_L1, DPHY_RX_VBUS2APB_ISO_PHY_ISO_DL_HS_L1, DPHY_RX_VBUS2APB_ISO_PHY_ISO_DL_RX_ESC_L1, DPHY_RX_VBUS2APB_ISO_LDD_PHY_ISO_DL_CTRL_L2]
0xC20 DPHY_RX_VBUS2APB_ISO_PHY_ISO_DL_CTRL_L1 — PHY_ISO_DL_CTRL_L1
  [31:7] BF_31_7 ro
  [6] S_CLK_SWAPDPDN_DL_L_1 rw — Drives S_Clk_SwapDpDn_dl_l_1
  [5] FORCERXMODE_DL_L_1 rw — Forces the DPHY_RX_VBUS2APB_LANE in Receiver mode ForceRxMode_dl_l_1
  [4] S_DATA_SWAPDPDN_DL_L_1 rw — Swaps the tx_p and tx_m differential pins S_Data_SwapDpDn_dl_l_1
  [3] S_STOPSTATE_DL_L_1 ro — Receives Lane Stop state status S_StopState_dl_l_1
  [2] S_ULPSACTIVENOT_DL_L_1 ro — Receives the Turnaround request S_ULPSActiveNot_dl_l_1
  [1] S_ENABLE_DL_L_1 rw — Enables the data DPHY_RX_VBUS2APB_LANE S_Enable_dl_l_1
  [0] LANE_READY_DL_L_1 ro — High Speed data DPHY_RX_VBUS2APB_LANE ready lane_ready_dl_l_1
0xC24 DPHY_RX_VBUS2APB_ISO_PHY_ISO_DL_HS_L1 ro — PHY_ISO_DL_HS_L1
  [31:14] BF_31_14
  [13] ERRSOTSYNCHS_DL_L_1 — Start of transmission error ErrSoTSyncHS_dl_l_1
  [12] ERRSOTHS_DL_L_1 — Start of transmission error ErrSoTHS_dl_l_1
  [11] RXSYNCHS_DL_L_1 — Stores the high speed receive synchronization RxSyncHS_dl_l_1
  [10] RXVALIDHS_DL_L_1 — High speed data receive data valid RxValidHS_dl_l_1
  [9] RXSKEWCALHS_DL_L_1 — High speed data receive dksew calibration RxSkewCalHS_dl_l_1
  [8] RXACTIVEHS_DL_L_1 — Stores the high speed data reception active RxActiveHS_dl_l_1
  [7:0] RXDATAHS_DL_L_1 — High speed receive data RxDataHS_dl_l_1
0xC28 DPHY_RX_VBUS2APB_ISO_PHY_ISO_DL_RX_ESC_L1 ro — PHY_ISO_DL_RX_ESC_L1
  [31:18] BF_31_18
  [17] S_ERRSYNC_DL_L_1 — Control error S_ErrControl_dl_l_1
  [16] S_ERRCONTROL_DL_L_1 — Control error S_ErrControl_dl_l_1
  [15] S_ERRESC_DL_L_1 — Escape entry error S_ErrEsc_dl_l_1
  [14:11] S_RXTRIGGERESC_DL_L_1 — Receive escape mode lower power trigger state S_RxTriggerEsc_dl_l_1
  [10] S_RXULPSESC_DL_L_1 — Receive escape mode ultra low power state S_RxULPSEsc_dl_l_1
  [9] S_RXVALIDESC_DL_L_1 — Receive escape mode data present S_RxValidEsc_dl_l_1
  [8] S_RXLPDTESC_DL_L_1 — Receive escape mode low power data indicator S_RxLPDTEsc_dl_l_1
  [7:0] S_RXDATAESC_DL_L_1 — Receive escape mode low power receive data S_RxDataEsc_dl_l_1
0xC2C DPHY_RX_VBUS2APB_ISO_PHY_ISO_SPARE_1 ro — PHY_ISO_SPARE_1
  [31:0] PHY_ISO_SPARE_1 — spare register
0xC30 DPHY_RX_VBUS2APB_ISO_LDD_PHY_ISO_DL_CTRL_L2 — PHY_ISO_DL_CTRL_L2
  [31:7] BF_31_7 ro
  [6] S_CLK_SWAPDPDN_DL_L_2 rw — Drives S_Clk_SwapDpDn_dl_l_2
  [5] FORCERXMODE_DL_L_2 rw — Forces the DPHY_RX_VBUS2APB_LANE in Receiver mode ForceRxMode_dl_l_2
  [4] S_DATA_SWAPDPDN_DL_L_2 rw — Swaps the tx_p and tx_m differential pins S_Data_SwapDpDn_dl_l_2
  [3] S_STOPSTATE_DL_L_2 ro — Receives Lane Stop state status S_StopState_dl_l_2
  [2] S_ULPSACTIVENOT_DL_L_2 ro — Receives the Turnaround request S_ULPSActiveNot_dl_l_2
  [1] S_ENABLE_DL_L_2 rw — Enables the data DPHY_RX_VBUS2APB_LANE S_Enable_dl_l_2
  [0] LANE_READY_DL_L_2 ro — High Speed data DPHY_RX_VBUS2APB_LANE ready lane_ready_dl_l_2
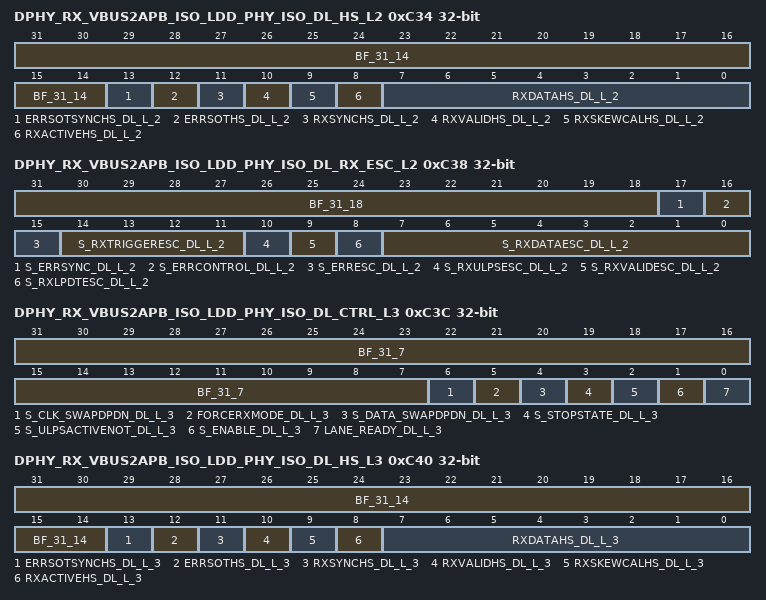
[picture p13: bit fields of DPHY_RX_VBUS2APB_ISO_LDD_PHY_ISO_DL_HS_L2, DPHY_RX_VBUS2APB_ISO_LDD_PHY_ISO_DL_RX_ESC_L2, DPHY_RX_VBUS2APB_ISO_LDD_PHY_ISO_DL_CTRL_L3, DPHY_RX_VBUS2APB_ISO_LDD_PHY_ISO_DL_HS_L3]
0xC34 DPHY_RX_VBUS2APB_ISO_LDD_PHY_ISO_DL_HS_L2 ro — PHY_ISO_DL_HS_L2
  [31:14] BF_31_14
  [13] ERRSOTSYNCHS_DL_L_2 — Start of transmission error ErrSoTSyncHS_dl_l_2
  [12] ERRSOTHS_DL_L_2 — Start of transmission error ErrSoTHS_dl_l_2
  [11] RXSYNCHS_DL_L_2 — Stores the high speed receive synchronization RxSyncHS_dl_l_2
  [10] RXVALIDHS_DL_L_2 — High speed data receive data valid RxValidHS_dl_l_2
  [9] RXSKEWCALHS_DL_L_2 — High speed data receive dksew calibration RxSkewCalHS_dl_l_2
  [8] RXACTIVEHS_DL_L_2 — Stores the high speed data reception active RxActiveHS_dl_l_2
  [7:0] RXDATAHS_DL_L_2 — High speed receive data RxDataHS_dl_l_2
0xC38 DPHY_RX_VBUS2APB_ISO_LDD_PHY_ISO_DL_RX_ESC_L2 ro — PHY_ISO_DL_RX_ESC_L2
  [31:18] BF_31_18
  [17] S_ERRSYNC_DL_L_2 — Control error S_ErrControl_dl_r_2
  [16] S_ERRCONTROL_DL_L_2 — Control error S_ErrControl_dl_l_2
  [15] S_ERRESC_DL_L_2 — Escape entry error S_ErrEsc_dl_l_2
  [14:11] S_RXTRIGGERESC_DL_L_2 — Receive escape mode lower power trigger state S_RxTriggerEsc_dl_l_2
  [10] S_RXULPSESC_DL_L_2 — Receive escape mode ultra low power state S_RxULPSEsc_dl_l_2
  [9] S_RXVALIDESC_DL_L_2 — Receive escape mode data present S_RxValidEsc_dl_l_2
  [8] S_RXLPDTESC_DL_L_2 — Receive escape mode low power data indicator S_RxLPDTEsc_dl_l_2
  [7:0] S_RXDATAESC_DL_L_2 — Receive escape mode low power receive data S_RxDataEsc_dl_l_2
0xC3C DPHY_RX_VBUS2APB_ISO_LDD_PHY_ISO_DL_CTRL_L3 — PHY_ISO_DL_CTRL_L3
  [31:7] BF_31_7 ro
  [6] S_CLK_SWAPDPDN_DL_L_3 rw — Drives S_Clk_SwapDpDn_dl_l_0
  [5] FORCERXMODE_DL_L_3 rw — Forces the DPHY_RX_VBUS2APB_LANE in Receiver mode ForceRxMode_dl_l_3
  [4] S_DATA_SWAPDPDN_DL_L_3 rw — Swaps the tx_p and tx_m differential pins S_Data_SwapDpDn_dl_l_3
  [3] S_STOPSTATE_DL_L_3 ro — Receives Lane Stop state status S_StopState_dl_l_3
  [2] S_ULPSACTIVENOT_DL_L_3 ro — Receives the Turnaround request S_ULPSActiveNot_dl_l_3
  [1] S_ENABLE_DL_L_3 rw — Enables the data DPHY_RX_VBUS2APB_LANE S_Enable_dl_l_3
  [0] LANE_READY_DL_L_3 ro — High Speed data DPHY_RX_VBUS2APB_LANE ready lane_ready_dl_l_3
0xC40 DPHY_RX_VBUS2APB_ISO_LDD_PHY_ISO_DL_HS_L3 ro — PHY_ISO_DL_HS_L3
  [31:14] BF_31_14
  [13] ERRSOTSYNCHS_DL_L_3 — Start of transmission error ErrSoTSyncHS_dl_l_3
  [12] ERRSOTHS_DL_L_3 — Start of transmission error ErrSoTHS_dl_l_3
  [11] RXSYNCHS_DL_L_3 — Stores the high speed receive synchronization RxSyncHS_dl_l_3
  [10] RXVALIDHS_DL_L_3 — High speed data receive data valid RxValidHS_dl_l_3
  [9] RXSKEWCALHS_DL_L_3 — High speed data receive dksew calibration RxSkewCalHS_dl_l_3
  [8] RXACTIVEHS_DL_L_3 — Stores the high speed data reception active RxActiveHS_dl_l_3
  [7:0] RXDATAHS_DL_L_3 — High speed receive data RxDataHS_dl_l_3
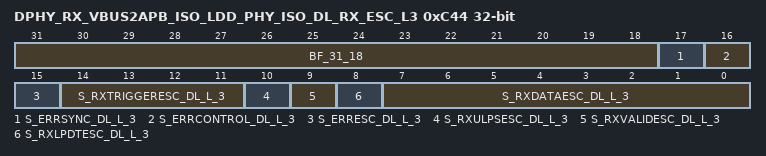
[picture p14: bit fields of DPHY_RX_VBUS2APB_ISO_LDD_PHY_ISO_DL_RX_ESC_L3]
0xC44 DPHY_RX_VBUS2APB_ISO_LDD_PHY_ISO_DL_RX_ESC_L3 ro — PHY_ISO_DL_RX_ESC_L3
  [31:18] BF_31_18
  [17] S_ERRSYNC_DL_L_3 — Control error S_ErrSync_dl_l_3
  [16] S_ERRCONTROL_DL_L_3 — Control error S_ErrControl_dl_l_3
  [15] S_ERRESC_DL_L_3 — Escape entry error S_ErrEsc_dl_l_3
  [14:11] S_RXTRIGGERESC_DL_L_3 — Receive escape mode lower power trigger state S_RxTriggerEsc_dl_l_3
  [10] S_RXULPSESC_DL_L_3 — Receive escape mode ultra low power state S_RxULPSEsc_dl_l_3
  [9] S_RXVALIDESC_DL_L_3 — Receive escape mode data present S_RxValidEsc_dl_l_3
  [8] S_RXLPDTESC_DL_L_3 — Receive escape mode low power data indicator S_RxLPDTEsc_dl_l_3
  [7:0] S_RXDATAESC_DL_L_3 — Receive escape mode low power receive data S_RxDataEsc_dl_l_3
0xC48 DPHY_RX_VBUS2APB_ISO_LDD_PHY_ISO_RX_SPARE_1 ro — PHY_ISO_RX_SPARE_1
  [31:0] PHY_ISO_RX_SPARE_1 — spare register
0xC4C DPHY_RX_VBUS2APB_ISO_LDD_PHY_ISO_RX_SPARE_2 ro — PHY_ISO_RX_SPARE_2
  [31:0] PHY_ISO_RX_SPARE_2 — spare register
